# PIC18LF4450 register map
Vendor: Microchip
Architecture 18xxxx. Special function registers and configuration words.
Registers are 8-bit, read-write, reset 0x0 unless marked. A register's access mark holds for its fields unless they carry their own. Addresses are absolute, and some are shared; only a register's first bit layout is shown; lines under a group give offsets from that group; [hi:lo] are bit positions; {n}, {i} and the like mark numbered series; 'fields as' and 'values as' point back to an identical list; <NAME> marks a mode.

## Further device data
pins=1: MCLR/Vpp/RE3; 2: RA0/AN0; 3: RA1/AN1; 4: RA2/AN2/Vref-; 5: RA3/AN3/Vref+; 6: RA4/T0CKI/RCV; 7: RA5/AN4/HLVDIN; 8: RE0/AN5; 9: RE1/AN6; 10: RE2/AN7; 11: Vdd; 12: Vss; 13: OSC1/CLKI; 14: OSC2/CLKO/RA6; 15: RC0/T1OSO/T1CKI; 16: RC1/T1OSI/UOE; 17: RC2/CCP1; 18: Vusb; 19: RD0; 20: RD1; 21: RD2; 22: RD3; 23: RC4/D-/VM; 24: RC5/D+/VP; 25: RC6/TX/CK; 26: RC7/RX/DT; 27: RD4; 28: RD5; 29: RD6; 30: RD7; 31: Vss; 32: Vdd; 33: RB0/AN12/INT0; 34: RB1/AN10/INT1; 35: RB2/AN8/INT2/VMO; 36: RB3/AN9/VPO; 37: RB4/AN11/KBI0; 38: RB5/KBI1/PGM; 39: RB6/KBI2/PGC; 40: RB7/KBI3/PGD

## SFR
0xF66 UFRML ro reset not defined — (power-on value xxxxxxxx)
  [7:0] FRM
0xF67 UFRMH ro reset not defined — (power-on value -----xxx)
  [2:0] FRM
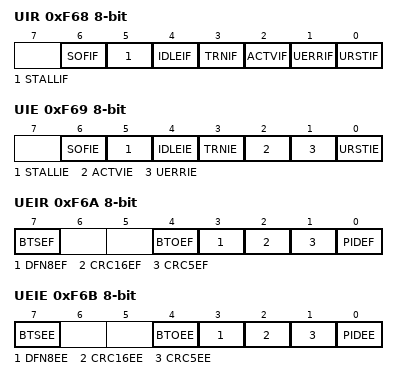
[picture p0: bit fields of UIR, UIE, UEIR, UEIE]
0xF68 UIR
  [6] SOFIF, [5] STALLIF, [4] IDLEIF, [3] TRNIF, [2] ACTVIF, [1] UERRIF ro, [0] URSTIF
0xF69 UIE
  [6] SOFIE, [5] STALLIE, [4] IDLEIE, [3] TRNIE, [2] ACTVIE, [1] UERRIE, [0] URSTIE
0xF6A UEIR
  [7] BTSEF — (can only be cleared)
  [4] BTOEF — (can only be cleared)
  [3] DFN8EF — (can only be cleared)
  [2] CRC16EF — (can only be cleared)
  [1] CRC5EF — (can only be cleared)
  [0] PIDEF — (can only be cleared)
0xF6B UEIE
  [7] BTSEE, [4] BTOEE, [3] DFN8EE, [2] CRC16EE, [1] CRC5EE, [0] PIDEE
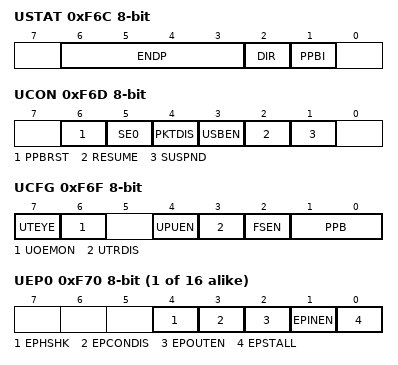
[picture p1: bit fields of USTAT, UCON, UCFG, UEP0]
0xF6C USTAT ro reset not defined — (power-on value -xxxxxx-)
  [6:3] ENDP, [2] DIR, [1] PPBI
0xF6D UCON reset not defined — (power-on value -0x0000-)
  [6] PPBRST
  [5] SE0 ro
  [4] PKTDIS — (can only be cleared)
  [3] USBEN
  [2] RESUME
  [1] SUSPND
0xF6E UADDR
  [6:0] ADDR
0xF6F UCFG
  [7] UTEYE, [6] UOEMON, [4] UPUEN, [3] UTRDIS, [2] FSEN, [1:0] PPB
{0xF70+i} UEP{i} (i=0..15)
  [4] EPHSHK, [3] EPCONDIS, [2] EPOUTEN, [1] EPINEN, [0] EPSTALL
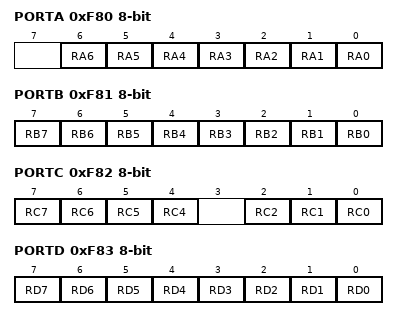
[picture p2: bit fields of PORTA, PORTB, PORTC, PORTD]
0xF80 PORTA reset not defined — (power-on value -x0x0000)
  [n] RA{n} (n=0..6)
0xF81 PORTB reset not defined — (power-on value xxxxxxxx)
  [n] RB{n} (n=0..7)
0xF82 PORTC reset not defined — (power-on value xxxx-xxx)
  [7] RC7, [6] RC6, [5] RC5 ro, [4] RC4 ro, [2] RC2, [1] RC1, [0] RC0
0xF83 PORTD reset not defined — (power-on value xxxxxxxx)
  [n] RD{n} (n=0..7)
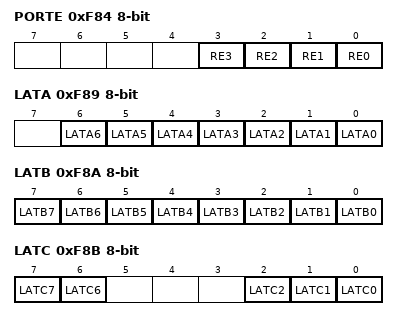
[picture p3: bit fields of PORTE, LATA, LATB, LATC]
0xF84 PORTE reset not defined — (power-on value ----xxxx)
  [3] RE3 ro, [2] RE2, [1] RE1, [0] RE0
0xF89 LATA reset not defined — (power-on value -xxxxxxx)
  [n] LATA{n} (n=0..6)
0xF8A LATB reset not defined — (power-on value xxxxxxxx)
  [n] LATB{n} (n=0..7)
0xF8B LATC reset not defined — (power-on value xxxx-xxx)
  [7] LATC7, [6] LATC6, [2] LATC2, [1] LATC1, [0] LATC0
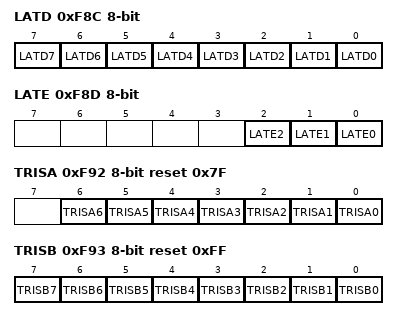
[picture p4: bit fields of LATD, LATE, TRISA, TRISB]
0xF8C LATD reset not defined — (power-on value xxxxxxxx)
  [n] LATD{n} (n=0..7)
0xF8D LATE reset not defined — (power-on value -----xxx)
  [2] LATE2, [1] LATE1, [0] LATE0
0xF92 TRISA reset 0x7F
  [n] TRISA{n} (n=0..6)
0xF93 TRISB reset 0xFF
  [n] TRISB{n} (n=0..7)
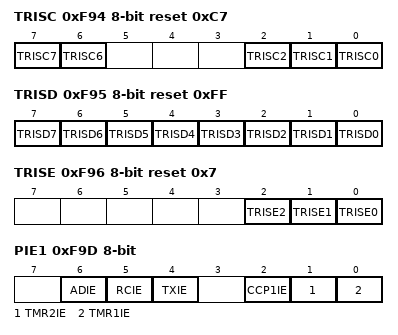
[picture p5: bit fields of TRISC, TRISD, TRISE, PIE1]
0xF94 TRISC reset 0xC7
  [7] TRISC7, [6] TRISC6, [2] TRISC2, [1] TRISC1, [0] TRISC0
0xF95 TRISD reset 0xFF
  [n] TRISD{n} (n=0..7)
0xF96 TRISE reset 0x7
  [2] TRISE2, [1] TRISE1, [0] TRISE0
0xF9D PIE1
  [6] ADIE, [5] RCIE, [4] TXIE, [2] CCP1IE, [1] TMR2IE, [0] TMR1IE
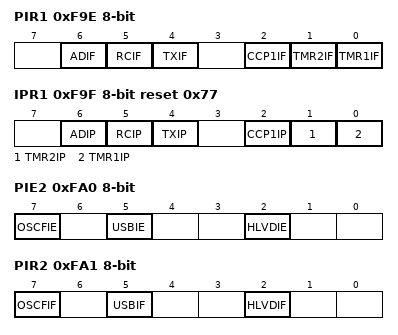
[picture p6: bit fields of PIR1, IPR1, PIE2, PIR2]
0xF9E PIR1
  [6] ADIF, [5] RCIF ro, [4] TXIF ro, [2] CCP1IF, [1] TMR2IF, [0] TMR1IF
0xF9F IPR1 reset 0x77
  [6] ADIP, [5] RCIP, [4] TXIP, [2] CCP1IP, [1] TMR2IP, [0] TMR1IP
0xFA0 PIE2
  [7] OSCFIE, [5] USBIE, [2] HLVDIE
0xFA1 PIR2
  [7] OSCFIF, [5] USBIF, [2] HLVDIF
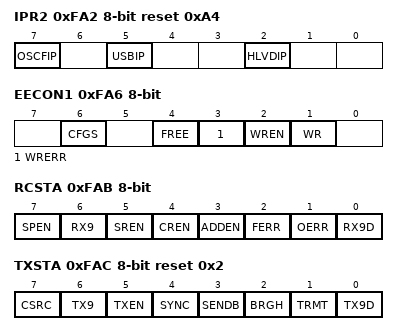
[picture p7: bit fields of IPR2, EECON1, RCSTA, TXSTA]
0xFA2 IPR2 reset 0xA4
  [7] OSCFIP, [5] USBIP, [2] HLVDIP
0xFA6 EECON1 reset not defined — (power-on value -x-0x00-)
  [6] CFGS
  [4] FREE
  [3] WRERR
  [2] WREN
  [1] WR — (can only be set)
0xFA7 EECON2 wo reset not defined
0xFAB RCSTA reset not defined — (power-on value 0000000x)
  [7] SPEN, [6] RX9, [5] SREN, [4] CREN, [3] ADDEN, [2] FERR ro, [1] OERR ro, [0] RX9D ro
0xFAC TXSTA reset 0x2
  [7] CSRC, [6] TX9, [5] TXEN, [4] SYNC, [3] SENDB, [2] BRGH, [1] TRMT ro, [0] TX9D
0xFAD TXREG wo
0xFAE RCREG ro
0xFAF SPBRG
0xFB0 SPBRGH
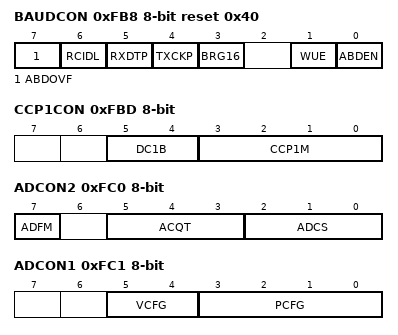
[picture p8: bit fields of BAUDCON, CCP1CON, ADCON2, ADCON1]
0xFB8 BAUDCON reset 0x40
  [7] ABDOVF — (can only be cleared)
  [6] RCIDL ro
  [5] RXDTP
  [4] TXCKP
  [3] BRG16
  [1] WUE
  [0] ABDEN
0xFBD CCP1CON
  [5:4] DC1B, [3:0] CCP1M
0xFBE CCPR1L reset not defined — (power-on value xxxxxxxx)
0xFBF CCPR1H reset not defined — (power-on value xxxxxxxx)
0xFC0 ADCON2
  [7] ADFM, [5:3] ACQT, [2:0] ADCS
0xFC1 ADCON1 reset not defined — (power-on value --00qqqq)
  [5:4] VCFG, [3:0] PCFG
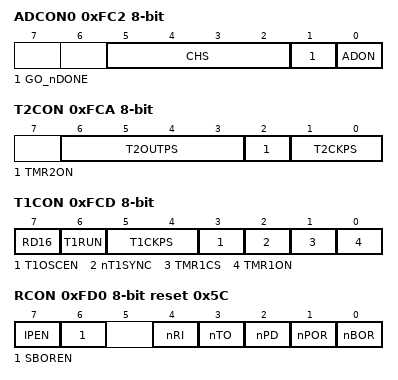
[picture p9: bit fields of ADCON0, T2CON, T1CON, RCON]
0xFC2 ADCON0
  [5:2] CHS, [1] GO_nDONE, [0] ADON
0xFC3 ADRESL reset not defined — (power-on value xxxxxxxx)
0xFC4 ADRESH reset not defined — (power-on value xxxxxxxx)
0xFCA T2CON
  [6:3] T2OUTPS, [2] TMR2ON, [1:0] T2CKPS
0xFCB PR2 reset 0xFF
0xFCC TMR2
0xFCD T1CON
  [7] RD16, [6] T1RUN ro, [5:4] T1CKPS, [3] T1OSCEN, [2] nT1SYNC, [1] TMR1CS, [0] TMR1ON
0xFCE TMR1L reset not defined — (power-on value xxxxxxxx)
0xFCF TMR1H reset not defined — (power-on value xxxxxxxx)
0xFD0 RCON reset 0x5C
  [7] IPEN, [6] SBOREN, [4] nRI, [3] nTO, [2] nPD, [1] nPOR, [0] nBOR
0xFD1 WDTCON
  [0] SWDTEN
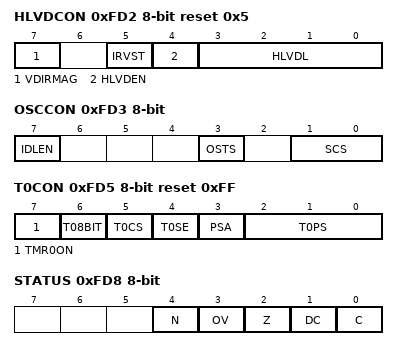
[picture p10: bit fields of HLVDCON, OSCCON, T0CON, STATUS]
0xFD2 HLVDCON reset 0x5
  [7] VDIRMAG, [5] IRVST, [4] HLVDEN, [3:0] HLVDL
0xFD3 OSCCON
  [7] IDLEN, [3] OSTS ro, [1:0] SCS
0xFD5 T0CON reset 0xFF
  [7] TMR0ON, [6] T08BIT, [5] T0CS, [4] T0SE, [3] PSA, [2:0] T0PS
0xFD6 TMR0L reset not defined — (power-on value xxxxxxxx)
0xFD7 TMR0H
0xFD8 STATUS reset not defined — (power-on value ---xxxxx)
  [4] N, [3] OV, [2] Z, [1] DC, [0] C
0xFD9 FSR2L reset not defined — (power-on value xxxxxxxx)
0xFDA FSR2H
  [3:0] FSR2H
0xFDB PLUSW2 access not given reset not defined
0xFDC PREINC2 access not given reset not defined
0xFDD POSTDEC2 access not given reset not defined
0xFDE POSTINC2 access not given reset not defined
0xFDF INDF2 access not given reset not defined
0xFE0 BSR
  [3:0] BSR
0xFE1 FSR1L reset not defined — (power-on value xxxxxxxx)
0xFE2 FSR1H
  [3:0] FSR1H
0xFE3 PLUSW1 access not given reset not defined
0xFE4 PREINC1 access not given reset not defined
0xFE5 POSTDEC1 access not given reset not defined
0xFE6 POSTINC1 access not given reset not defined
0xFE7 INDF1 access not given reset not defined
0xFE8 WREG reset not defined — (power-on value xxxxxxxx)
0xFE9 FSR0L reset not defined — (power-on value xxxxxxxx)
0xFEA FSR0H
  [3:0] FSR0H
0xFEB PLUSW0 access not given reset not defined
0xFEC PREINC0 access not given reset not defined
0xFED POSTDEC0 access not given reset not defined
0xFEE POSTINC0 access not given reset not defined
0xFEF INDF0 access not given reset not defined
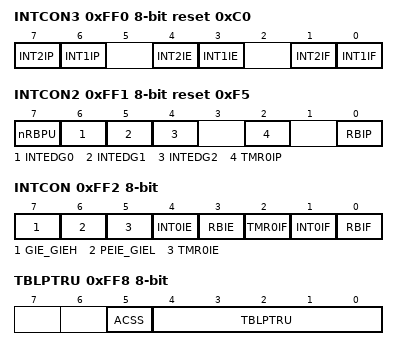
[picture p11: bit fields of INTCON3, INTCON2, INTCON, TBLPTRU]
0xFF0 INTCON3 reset 0xC0
  [7] INT2IP, [6] INT1IP, [4] INT2IE, [3] INT1IE, [1] INT2IF, [0] INT1IF
0xFF1 INTCON2 reset 0xF5
  [7] nRBPU, [6] INTEDG0, [5] INTEDG1, [4] INTEDG2, [2] TMR0IP, [0] RBIP
0xFF2 INTCON reset not defined — (power-on value 0000000x)
  [7] GIE_GIEH, [6] PEIE_GIEL, [5] TMR0IE, [4] INT0IE, [3] RBIE, [2] TMR0IF, [1] INT0IF, [0] RBIF
0xFF3 PRODL reset not defined — (power-on value xxxxxxxx)
0xFF4 PRODH reset not defined — (power-on value xxxxxxxx)
0xFF5 TABLAT
0xFF6 TBLPTRL
0xFF7 TBLPTRH
0xFF8 TBLPTRU
  [5] ACSS, [4:0] TBLPTRU
0xFF9 PCL
0xFFA PCLATH
  [7:0] PCH
0xFFB PCLATU
  [4:0] PCU
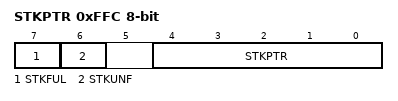
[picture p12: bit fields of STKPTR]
0xFFC STKPTR
  [7] STKFUL — (can only be cleared)
  [6] STKUNF — (can only be cleared)
  [4:0] STKPTR
0xFFD TOSL
0xFFE TOSH
0xFFF TOSU
  [4:0] TOSU
